# STM32U585 register map
File version: 2.2
CPU: CM33 r0p1, little endian, MPU, FPU, 4 interrupt priority bits
Registers are 32-bit, read-write, reset 0x0 unless marked. A register's access mark holds for its fields unless they carry their own. Offsets are from the block's base; [hi:lo] are bit positions; {n}, {i} and the like mark numbered series; 'fields as' and 'values as' point back to an identical list.

## DLYBOS1 — The delay block (DLYB) is used to generate an output clock that is dephased from the input clock
Base 0x420CF000
Same registers: DLYBSD1 0x420C8400, DLYBSD2 0x420C8800, DLYBOS2 0x420CF400, SEC_DLYBSD1 0x520C8400, SEC_DLYBSD2 0x520C8800, SEC_DLYBOS1 0x520CF000, SEC_DLYBOS2 0x520CF400
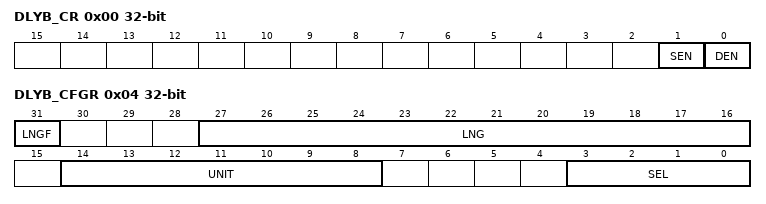
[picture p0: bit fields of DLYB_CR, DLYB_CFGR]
0x00 DLYB_CR — control register
  [1] SEN — OPALPM
  [0] DEN — Operational amplifier Enable
0x04 DLYB_CFGR access per field — configuration register
  [31] LNGF ro, [27:16] LNG ro, [14:8] UNIT rw, [3:0] SEL rw

## PSSI
Base 0x4202C400
Same registers: SEC_PSSI 0x5202C400
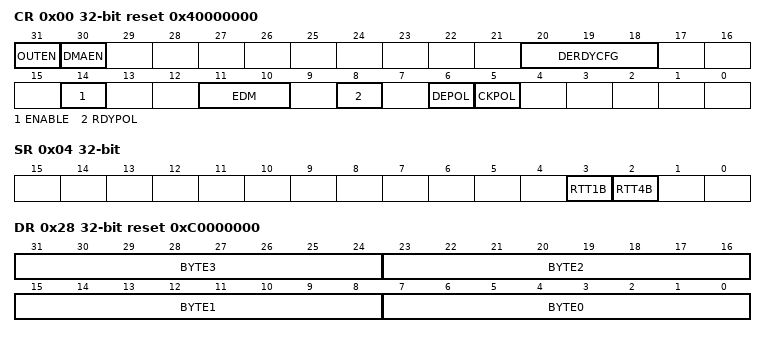
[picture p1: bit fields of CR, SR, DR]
0x00 CR reset 0x40000000 — PSSI control register
  [31] OUTEN — Data direction selection bit
  [30] DMAEN — DMA enable bit
  [20:18] DERDYCFG — Data enable and ready configuration
  [14] ENABLE — PSSI enable
  [11:10] EDM — Extended data mode
  [8] RDYPOL — Ready (PSSI_RDY) polarity
  [6] DEPOL — Data enable (PSSI_DE) polarity
  [5] CKPOL — Parallel data clock polarity
0x04 SR ro — PSSI status register
  [3] RTT1B, [2] RTT4B
0x08 RIS ro — PSSI raw interrupt status register
  [1] OVR_RIS
0x0C IER — PSSI interrupt enable register
  [1] OVR_IE
0x10 MIS ro — PSSI masked interrupt status register
  [1] OVR_MIS
0x14 ICR wo — PSSI interrupt clear register
  [1] OVR_ISC
0x28 DR reset 0xC0000000 — PSSI data register
  [8n+7:8n] BYTE{n} (n=0..3) — Data byte {n}

## OTFDEC1 — On-The-Fly Decryption engine
Base 0x420C5000
Same registers: OTFDEC2 0x420C5400, SEC_OTFDEC1 0x520C5000, SEC_OTFDEC2 0x520C5400
0x00 CR — OTFDEC control register
  [0] ENC — Encryption mode bit
0x10 PRIVCFGR — OTFDEC privileged access control configuration register
  [0] PRIV — Encryption mode bit
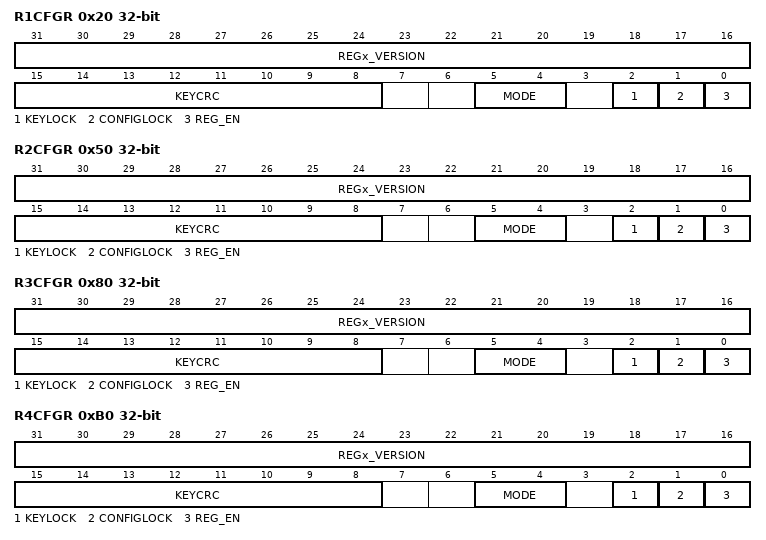
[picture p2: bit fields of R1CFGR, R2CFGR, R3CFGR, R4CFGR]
0x20 R1CFGR access per field — OTFDEC region x configuration
  [31:16] REGx_VERSION rw — region firmware version
  [15:8] KEYCRC ro — region key 8-bit CRC
  [5:4] MODE rw — operating mode
  [2] KEYLOCK rw — region key lock
  [1] CONFIGLOCK rw — region config lock
  [0] REG_EN rw — region on-the-fly decryption
0x24 R1STARTADDR — OTFDEC region x start address
  [31:0] REGx_START_ADDR — Region AXI start address
0x28 R1ENDADDR reset 0xFFF — OTFDEC region x end address
  [31:0] REGx_END_ADDR — Region AXI end address
0x2C R1NONCER0 — OTFDEC region x nonce register
  [31:0] REGx_NONCE
0x30 R1NONCER1 — OTFDEC region x nonce register
  [31:0] REGx_NONCE — Region nonce
{0x4+0x30*i} R{i}KEYR0 wo (i=1..4) — OTFDEC region x key register 0
  [31:0] REGx_KEY
{0x8+0x30*i} R{i}KEYR1 wo (i=1..4) — OTFDEC region x key register 1
  [31:0] REGx_KEY
0x3C R1KEYR2 wo — OTFDEC region x key register 2
  [31:0] REGx_KEY
{0x10+0x30*i} R{i}KEYR3 wo (i=1..4) — OTFDEC region x key register 3
  [31:0] REGx_KEY
0x50 R2CFGR access per field — OTFDEC region x configuration
  fields as R1CFGR
0x54 R2STARTADDR — OTFDEC region x start address
  [31:0] REGx_START_ADDR — Region AXI start address
0x58 R2ENDADDR reset 0xFFF — OTFDEC region x end address
  [31:0] REGx_END_ADDR — Region AXI end address
0x5C R2NONCER0 — OTFDEC region x nonce register
  [31:0] REGx_NONCE
0x60 R2NONCER1 — OTFDEC region x nonce register
  [31:0] REGx_NONCE — Region nonce, bits
0x6C R2KEYR2 wo — OTFDEC region x key register 2
  [31:0] REGx_KEY_
0x80 R3CFGR access per field — OTFDEC region x configuration
  fields as R1CFGR
0x84 R3STARTADDR — OTFDEC region x start address
  [31:0] REGx_START_ADDR — Region AXI start address
0x88 R3ENDADDR reset 0xFFF — OTFDEC region x end address
  [31:0] REGx_END_ADDR — Region AXI end address
0x8C R4ENDADDR reset 0xFFF — OTFDEC region x end address
  [31:0] REGx_END_ADDR — Region AXI end address
0x8C R3NONCER0 (alternate view of R4ENDADDR) — OTFDEC region x nonce register
  [31:0] REGx_NONCE
0x90 R3NONCER1 — OTFDEC region x nonce register
  [31:0] REGx_NONCE
0x9C R3KEYR2 wo — OTFDEC region x key register 2
  [31:0] REGx_KEY
0xB0 R4CFGR access per field — OTFDEC region x configuration
  fields as R1CFGR
0xB4 R4STARTADDR — OTFDEC region x start address
  [31:0] REGx_START_ADDR — Region AXI start address
0xBC R4NONCER0 — OTFDEC region x nonce register
  [31:0] REGx_NONCE
0xC0 R4NONCER1 — OTFDEC region x nonce register
  [31:0] REGx_NONCE
0xCC R4KEYR2 wo — OTFDEC region x key register 2
  [31:0] REGx_KEY
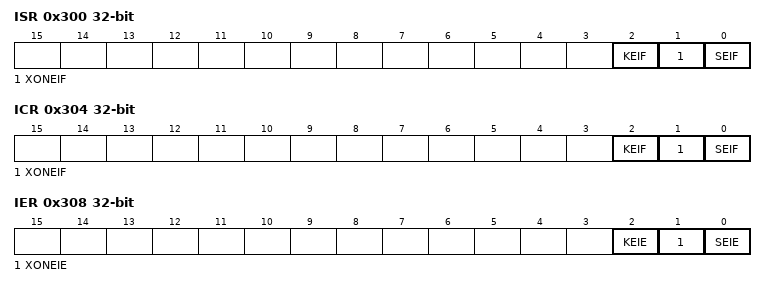
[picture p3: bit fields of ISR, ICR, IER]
0x300 ISR ro — OTFDEC interrupt status
  [2] KEIF — Key Error Interrupt Flag
  [1] XONEIF — Execute-only execute-Never Error
  [0] SEIF — Security Error Interrupt Flag
0x304 ICR ro — OTFDEC interrupt clear
  [2] KEIF
  [1] XONEIF — Execute-only execute-Never Error
  [0] SEIF
0x308 IER — OTFDEC interrupt enable
  [2] KEIE
  [1] XONEIE
  [0] SEIE — Security Error Interrupt
